# 3066H register map
File version: 1.0
Registers are 32-bit, access per field, reset 0x0 unless marked. A register's access mark holds for its fields unless they carry their own. Offsets are from the block's base; [hi:lo] are bit positions; {n}, {i} and the like mark numbered series.

## GPIO0 — GPIO0 peripheral interface
Base 0x1C000000
Same registers: GPIO{n} {0x14500000+0x1000*n} (n=1..16)
{0x0+4i} GPIO_DATA{i} (i=0..255) 8-bit rw — GPIO_DATA为GPIO数据寄存器，用来对输入或输出数据进行缓存。当配置GPIO_DIR中对应位为输出时，写入GPIO_DATA寄存器的值将会输出到相应的GPIO；如果配置为输入时，将会读取相应输入GPIO的值。 当GPIO_DIR相应的比特配置为输入时，有效读取的结果将返回GPIO的值；当配置为输出的时候，有效读取的结果将返回写入的值。 GPIO_DATA寄存器利用偏移地址Offset Address实现了读写寄存器比特的屏蔽操作。GPIO_DATA是一组寄存器的统称，对应256个地址空间，0x000 ~ 0x3FC，每个寄存器都有8bit。Offset Address bit[9:2]分别对应GPIO_DATA bit[7:0]，当相应的bit为高时，则可以对相应的位进行读写操作；反之，若对应bit为低则不能进行读写操作。如图9-2所示。 图9-2 比特屏蔽对应关系 例如： 若地址为0x3FC（0b11_1111_1100），则对GPIO_DATA bit[7:0]这8bit读写操作全部有效。 若地址为0x328（0b11_0010_1000），则对GPIO_DATA bit[7]、GPIO_DATA bit[6]、GPIO_DATA bit[3]、GPIO_DATA bit[1]的读写操作有效。 若地址为0x000（0b00_0000_0000），则任意读写操作均无效。 若地址为0x200（0b10_0000_0000），则仅对GPIO_DATA bit[7]的读写操作有效。
  [7:0] gpio_data — 当GPIO配置为输入模式时，为GPIO输入数据；当GPIO配置为输出模式时，为输出数据。各比特均可独立控制。与GPIO_DIR配合使用。
0x404 GPIO_IS 8-bit rw — GPIO_IS为GPIO中断触发寄存器。用来配置GPIO触发电平方式。
  [7:0] gpio_is — GPIO中断触发控制寄存器，bit[7:0]分别对应GPIO_DATA bit[7:0]，各比特独立控制。 0：边沿触发中断； 1：电平触发中断。
0x408 GPIO_IBE 8-bit rw — GPIO_IBE为GPIO双沿触发中断寄存器。用来配置GPIO沿触发方式。
  [7:0] gpio_ibe — GPIO中断沿触发控制寄存器，bit[7:0]分别对应GPIO_DATA bit[7:0]，各比特独立控制。 0：单边沿触发中断，具体是上升沿还是下降沿触发由GPIO_IEV控制； 1：双边触发中断。
0x40C GPIO_IEV 8-bit rw — GPIO_IEV为GPIO触发中断条件寄存器。用来配置GPIO触发中断条件。
  [7:0] gpio_iev — GPIO触发中断条件寄存器，bit[7:0]分别对应GPIO_DATA bit[7:0]，各比特独立控制。 0：下降沿或低电平触发中断，具体由GPIO_IS控制； 1：上升沿或高电平触发中断。
0x410 GPIO_IE 8-bit rw — GPIO_IE为GPIO中断屏蔽寄存器。用来屏蔽GPIO中断。
  [7:0] gpio_ie — GPIO中断屏蔽寄存器，bit[7:0]分别对应GPIO_DATA bit[7:0]，各比特独立控制。 0：屏蔽中断； 1：不屏蔽中断。
0x414 GPIO_RIS 8-bit ro — GPIO_RIS为GPIO原始中断状态寄存器。用来查询GPIO原始中断状态。
  [7:0] gpio_ris — GPIO原始中断寄存器，bit[7:0]分别对应GPIO_DATA bit[7:0]，指示未屏蔽的中断状态。该状态不受GPIO_IE寄存器屏蔽控制。 0：未发生中断； 1：已发生中断。
0x418 GPIO_MIS 8-bit ro — GPIO_MIS为GPIO屏蔽状态中断寄存器。用来查询GPIO屏蔽后的中断状态。对所有位进行或操作得到中断输出gpio_int。
  [7:0] gpio_mis — GPIO屏蔽后中断寄存器，bit[7:0]分别对应GPIO_DATA bit[7:0]，指示经屏蔽后的中断状态。该状态受GPIO_IE寄存器屏蔽控制。 0：中断无效； 1：中断有效。
0x41C GPIO_IC 8-bit rw — GPIO_IC为GPIO中断清除寄存器。用来清除GPIO产生的中断，同时清除GPIO_RIS寄存器和GPIO_MIS寄存器。
  [7:0] gpio_ic write-clears — GPIO中断清除寄存器，bit[7:0]分别对应GPIO_DATA bit[7:0]，各bit可独立控制。 0：无影响； 1：清除中断。
0x424 GPIO_OUTINV 8-bit rw — GPIO_OUTINV为GPIO输出极性翻转配置寄存器。用来快速翻转输出电平极性。
  [7:0] gpio_outinv — GPIO输出极性翻转配置寄存器。bit[7:0]分别对应GPIO_DATA bit[7:0]，各bit可独立控制。 0：输出维持不变； 1：输出极性发生翻转。 写1进行翻转。
{0x428+4i} GPIO_CPU{i}_INT_EN 8-bit rw (i=0..2) — GPIO_CPU{i}_INT_EN为GPIO送给CPU{i}的中断使能寄存器。用来控制中断是否上报给CPU{i}。
  [7:0] gpio_cpu{i}_int_en — GPIO_MIS对应的8bit中断是否上报给CPU{i}，分别对应bit[7:0]，各bit可独立控制。 0：不上报； 1：上报。
0x434 PORT_DA_MON 8-bit ro — PORT_DA_MON为端口输出监控数据寄存器。用来获取端口数据。
  [7:0] port_da — 端口data。
0x500 GPIO_DIR 8-bit rw — GPIO_DIR为GPIO方向控制寄存器。用来配置GPIO方向，偏移地址为0x500+n*0x4，n为Pin脚号（0~7），比如要配置GPIOx_1方向，则需要配置偏移地址0x504的bit[0]。
  [0] gpio_dir — GPIO方向控制寄存器，用来配置GPIO管脚方向。对应GPIO_DATA[0]。 0：输入； 1：输出。

## DAC0 — DAC0 peripheral interface
Base 0x18400000
Same registers: DAC1 0x18401000, DAC2 0x18402000, DAC3 0x18403000, DAC4 0x18404000, DAC5 0x18405000, DAC6 0x18406000, DAC7 0x18407000, DACBUFF 0x18408000
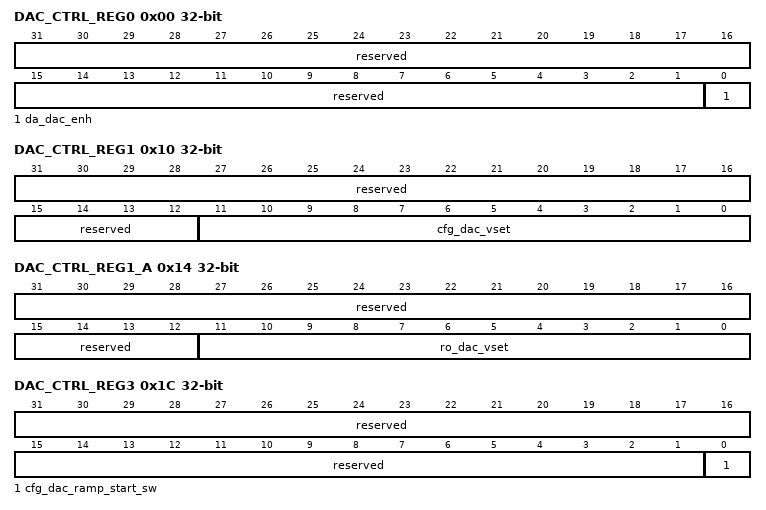
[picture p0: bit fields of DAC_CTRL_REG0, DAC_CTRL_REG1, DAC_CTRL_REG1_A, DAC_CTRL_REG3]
0x00 DAC_CTRL_REG0 — DAC控制寄存器0。
  [31:1] reserved ro — 保留。
  [0] da_dac_enh rw — DAC使能信号。
0x10 DAC_CTRL_REG1 — DAC控制寄存器1。
  [31:12] reserved ro — 保留。
  [11:0] cfg_dac_vset rw — DAC电压档位。
0x14 DAC_CTRL_REG1_A ro — DAC控制寄存器1的活动寄存器。
  [31:12] reserved — 保留。
  [11:0] ro_dac_vset — DAC电压活动值，被DAC转换为模拟电压。
0x18 DAC_CTRL_REG2 — DAC控制寄存器2。
  [31:24] reserved ro — 保留。
  [31:22] cfg_dac_debug_mode rw — Debug行为，控制RAMP在debug时的行为。 00：Debug时立即暂停RAMP； 01：Debug时完成当前RAMP在下一个APTSYNCP有效时暂停RAMP； 1X：RAMP不暂停。
  [21] reserved ro — 保留。
  [20] cfg_dac_ramp_dir rw — RAMP方向控制。 0：递减RAMP； 1：递增RAMP。
  [19:17] reserved rw — 保留。
  [16] cfg_dac_ramp_xtrig rw — RAMP交叉触发启动。 0：RAMP启动由APTSYNCP触发； 1：RAMP启动由窗口比较器的另一路RAMP结束触发。 RAMP启动同时也受cfg_dac_ramp_start_sw软件配置触发。
  [15] cfg_dac_ramp_load_sel rw — 当ACMP_RSLT_REG30.3.3.12-ACMP_RSLT_REG[cmp_filter_rslt]比较器滤波结果上升沿触发时，选择DAC_RAMP_STSDAC_RAMP_STS[ro_dac_ramp_sts]从缓存值DAC_RAMP_REG1DAC_RAMP_REG1[cfg_dac_ramp_ref]还是从活动值DAC_RAMP_REG1_ADAC_RAMP_REG1_A[ro_dac_ramp_ref]加载。 0：从活动值加载； 1：从缓存值加载。
  [14:8] reserved rw — 保留。
  [7:4] cfg_dac_syncp rw — APTSYNCP选择。 0x0：APT0SYNCP； 0x1：APT1SYNCP； 0x2：APT2SYNCP； … 0xF：APT15SYNCP。
  [1] cfg_dac_vset_load rw — DAC电压缓存加载。 0：实时加载。DAC_CTRL_REG1DAC_CTRL_REG1[cfg_dac_vset]实时加载到DAC_CTRL_REG1_ADAC_CTRL_REG1_A[ro_dac_vset]； 1：APTSYNCP有效时加载。
  [0] cfg_dac_vset_src rw — DAC电压配置源。 0：来自DAC_CTRL_REG1_ADAC_CTRL_REG1_A[ro_dac_vset]； 1：来自RAMP，DAC_RAMP_STSDAC_RAMP_STS[ro_dac_ramp_sts]。
0x1C DAC_CTRL_REG3 — DAC控制寄存器3。
  [31:1] reserved ro — 保留。
  [0] cfg_dac_ramp_start_sw W1_PULSE — DAC RAMP软件配置启动。写1清0。RAMP启动受cfg_dac_ramp_xtrig选择的硬件触发，同时也受此位域软件配置触发。
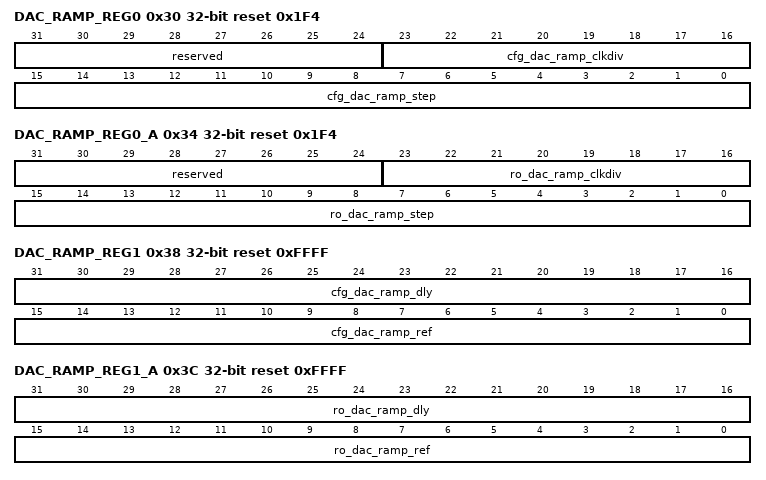
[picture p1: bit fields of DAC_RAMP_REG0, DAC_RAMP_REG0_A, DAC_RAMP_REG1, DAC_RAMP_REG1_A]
0x30 DAC_RAMP_REG0 reset 0x1F4 — DAC RAMP控制寄存器0。
  [31:24] reserved ro — 保留。
  [23:16] cfg_dac_ramp_clkdiv rw — DAC RAMP时钟分频系数缓存值。 0x0：不分频； 0x1：2分频； 0x2：3分频； … 0xFF：256分频。
  [15:0] cfg_dac_ramp_step rw — DAC RAMP步长缓存值。
0x34 DAC_RAMP_REG0_A reset 0x1F4 — DAC RAMP控制寄存器0的活动寄存器。
  [31:24] reserved ro — 保留。
  [23:16] ro_dac_ramp_clkdiv ro — DAC RAMP时钟分频系数缓存的活动值。
  [15:0] ro_dac_ramp_step rw — DAC RAMP步长缓存的活动值。
0x38 DAC_RAMP_REG1 reset 0xFFFF — DAC RAMP控制寄存器1。
  [31:16] cfg_dac_ramp_dly rw — DAC RAMP启动延时值缓存。
  [15:0] cfg_dac_ramp_ref ro — DAC RAMP参考值缓存。
0x3C DAC_RAMP_REG1_A ro reset 0xFFFF — DAC RAMP控制寄存器1的活动寄存器。
  [31:16] ro_dac_ramp_dly — DAC RAMP启动延时值缓存的活动值。
  [15:0] ro_dac_ramp_ref — DAC RAMP参考值缓存的活动值。
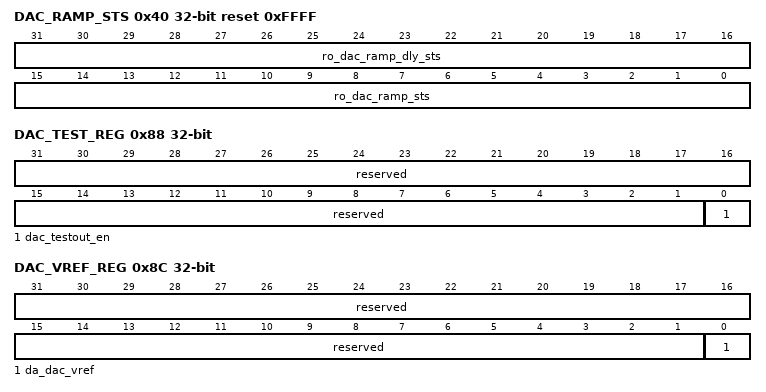
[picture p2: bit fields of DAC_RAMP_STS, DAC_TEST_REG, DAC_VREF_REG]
0x40 DAC_RAMP_STS ro reset 0xFFFF — DAC RAMP状态寄存器。
  [31:16] ro_dac_ramp_dly_sts — DAC RAMP延时实时值。
  [15:0] ro_dac_ramp_sts — DAC RAMP实时值。
0x88 DAC_TEST_REG — DAC测试寄存器。
  [31:1] reserved ro — 保留。
  [0] dac_testout_en rw — DAC输出观测使能。 0：关闭； 1：使能。
0x8C DAC_VREF_REG — DAC测试寄存器。
  [31:1] reserved ro — 保留。
  [0] da_dac_vref rw — DAC参考电压选择。 0：VDDA； 1：VDAC。
